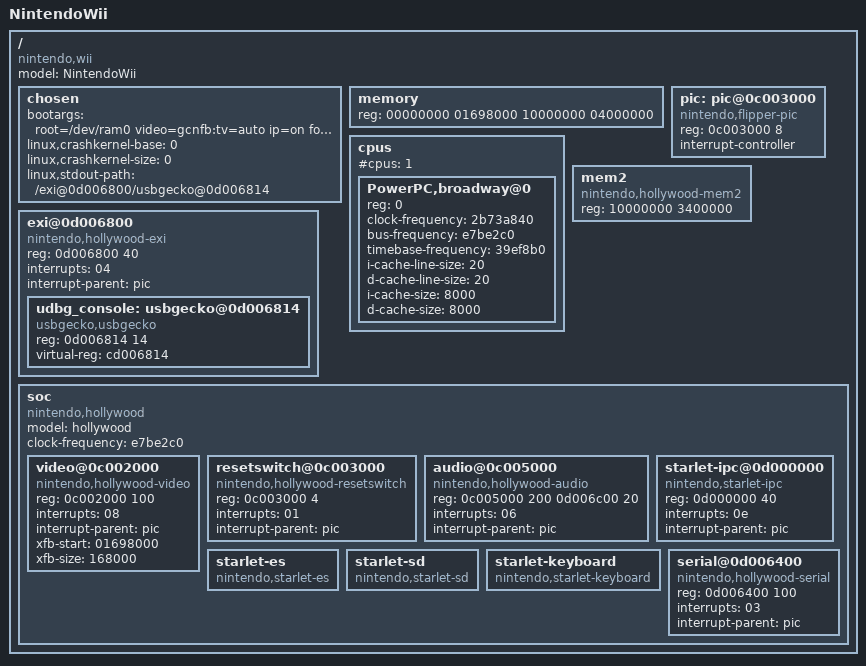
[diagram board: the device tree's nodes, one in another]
/*
 * arch/powerpc/boot/dts/wii.dts
 *
 * Nintendo Wii platform device tree source
 * Copyright (C) 2008 The GameCube Linux Team
 * Copyright (C) 2008 Albert Herranz
 *
 * This program is free software; you can redistribute it and/or
 * modify it under the terms of the GNU General Public License
 * as published by the Free Software Foundation; either version 2
 * of the License, or (at your option) any later version.
 *
 */

/ {
	model = "NintendoWii";
	compatible = "nintendo,wii";
	#address-cells = <1>;
	#size-cells = <1>;

	chosen {
		bootargs = "root=/dev/ram0 video=gcnfb:tv=auto ip=on force_keyboard_port=4"; 
		linux,crashkernel-base = <0>;
		linux,crashkernel-size = <0>;
		linux,stdout-path = "/exi@0d006800/usbgecko@0d006814";
	};

	memory {
		device_type = "memory";
		/* 24M minus framebuffer memory area (640*576*2*2) */
		reg = <00000000 01698000	/* only 1st range is used */
		       10000000 04000000>;
	};

	cpus {
		#cpus = <1>;
		#address-cells = <1>;
		#size-cells = <0>;

		PowerPC,broadway@0 {
			device_type = "cpu";
			reg = <0>;
			clock-frequency = <2b73a840>; /* 729MHz */
			bus-frequency = <e7be2c0>; /* 243MHz core-to-bus 3x */
			timebase-frequency = <39ef8b0>; /* 243MHz / 4 */
			/* Following required by dtc but not used */
			i-cache-line-size = <20>;
			d-cache-line-size = <20>;
			i-cache-size = <8000>;
			d-cache-size = <8000>;
		};
	};

	pic: pic@0c003000 {
		#interrupt-cells = <1>;
		compatible = "nintendo,flipper-pic";
		reg = <0c003000 8>;
		interrupt-controller;
	};

	/* MEM2 memory, discontiguous */
	mem2 {
		compatible = "nintendo,hollywood-mem2";
		reg = <10000000 3400000>; /* 52M of MEM2 RAM */
	};

	/* External Interface bus */
	exi@0d006800 {
		#address-cells = <1>;
		#size-cells = <1>;
		compatible = "nintendo,hollywood-exi";
		reg = <0d006800 40>;
		interrupts = <04>;
		interrupt-parent = <&pic>;

		udbg_console: usbgecko@0d006814 {
			compatible = "usbgecko,usbgecko";
			reg = <0d006814 14>;
			virtual-reg = <cd006814>;
		};
	};

	/* devices contained in the hollywood chipset */
	soc {
		#address-cells = <1>;
		#size-cells = <1>;
		#interrupt-cells = <1>;
		model = "hollywood";
		compatible = "nintendo,hollywood";
		clock-frequency = <e7be2c0>; /* 243MHz */
		ranges = <0c000000 0c000000 00010000 
			  0d000000 0d000000 00010000>;

		video@0c002000 {
			compatible = "nintendo,hollywood-video";
			reg = <0c002000 100>;
			interrupts = <08>;
			interrupt-parent = <&pic>;
			xfb-start = <01698000>; /* end-of-ram - xfb-size */
			xfb-size = <168000>;
		};

		resetswitch@0c003000 {
			compatible = "nintendo,hollywood-resetswitch";
			reg = <0c003000 4>;
			interrupts = <01>;
			interrupt-parent = <&pic>;
		};

		audio@0c005000 {
			compatible = "nintendo,hollywood-audio";
			reg = <0c005000 200	/* DSP */
			       0d006c00 20>;	/* AI */
			interrupts = <06>;
			interrupt-parent = <&pic>;
		};

		starlet-ipc@0d000000 {
			compatible = "nintendo,starlet-ipc";
			reg = <0d000000 40>;
			interrupts = <0e>;
			interrupt-parent = <&pic>;

		};

		starlet-es {
			compatible = "nintendo,starlet-es";
		};

		starlet-sd {
			compatible = "nintendo,starlet-sd";
		};

		starlet-keyboard {
			compatible = "nintendo,starlet-keyboard";
		};

		serial@0d006400 {
			compatible = "nintendo,hollywood-serial";
			reg = <0d006400 100>;
			interrupts = <03>;
			interrupt-parent = <&pic>;
		};
	};
};

